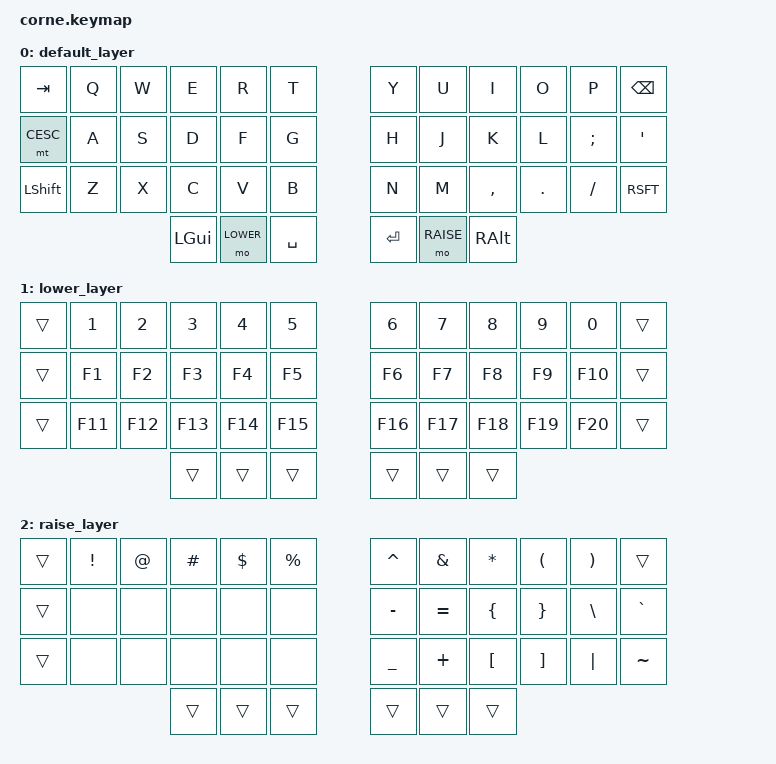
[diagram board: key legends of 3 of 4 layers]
/*
 * Copyright (c) 2020 The ZMK Contributors
 *
 * SPDX-License-Identifier: MIT
 */

#include <behaviors.dtsi>
#include <dt-bindings/zmk/keys.h>
#include <dt-bindings/zmk/bt.h>
#include <dt-bindings/zmk/outputs.h>

#define DEFAULT 0
#define LOWER   1
#define RAISE   2
#define ADJUST  3

#define CESC LCTRL ESC
#define BS(X) BT_SEL X


// Tapping term for mod-tap
&mt {
    tapping-term-ms = <150>;
};

&soft_off {
    hold-time-ms = <3000>;
};

/ {
        conditional_layers {
                compatible = "zmk,conditional-layers";
                tri_layer {
                        if-layers = <LOWER RAISE>;
                        then-layer = <ADJUST>;
                };
        };

        keymap {
                compatible = "zmk,keymap";

                default_layer {
                        bindings = <
//|--------+--------+--------+--------+--------+--------|                    |--------+--------+--------+--------+--------+--------|
    &kp TAB    &kp Q    &kp W    &kp E    &kp R    &kp T                         &kp Y    &kp U    &kp I    &kp O    &kp P &kp BSPC
//|--------+--------+--------+--------+--------+--------|                    |--------+--------+--------+--------+--------+--------|
   &mt CESC    &kp A    &kp S    &kp D    &kp F    &kp G                         &kp H    &kp J    &kp K    &kp L &kp SEMI  &kp SQT
//|--------+--------+--------+--------+--------+--------|                    |--------+--------+--------+--------+--------+--------|
   &kp LSHFT   &kp Z    &kp X    &kp C    &kp V    &kp B                         &kp N    &kp M &kp COMMA &kp DOT &kp FSLH &kp RSFT
//|--------+--------+--------+--------+--------+--------+--------|  |--------+--------+--------+--------+--------+--------+--------|
                                     &kp LGUI &mo LOWER &kp SPACE   &kp RET  &mo RAISE &kp RALT
                                  //`----------------------------'  `--------------------------'
                        >;
                };

                lower_layer {
                        bindings = <
//|--------+--------+--------+--------+--------+--------|                    |--------+--------+--------+--------+--------+--------|
     &trans   &kp N1   &kp N2   &kp N3   &kp N4   &kp N5                        &kp N6   &kp N7   &kp N8   &kp N9   &kp N0   &trans
//|--------+--------+--------+--------+--------+--------|                    |--------+--------+--------+--------+--------+--------|
     &trans   &kp F1   &kp F2   &kp F3   &kp F4   &kp F5                        &kp F6   &kp F7   &kp F8   &kp F9  &kp F10   &trans
//|--------+--------+--------+--------+--------+--------|                    |--------+--------+--------+--------+--------+--------|
     &trans  &kp F11  &kp F12  &kp F13  &kp F14  &kp F15                       &kp F16  &kp F17  &kp F18  &kp F19  &kp F20   &trans
//|--------+--------+--------+--------+--------+--------+--------|  |--------+--------+--------+--------+--------+--------+--------|
                                         &trans   &trans   &trans      &trans   &trans   &trans
                                  //`----------------------------'  `--------------------------'
                        >;
                };

                raise_layer {
                        bindings = <
//|--------+--------+--------+--------+--------+--------|                    |--------+--------+--------+--------+--------+--------|
     &trans &kp EXCL   &kp AT &kp HASH &kp DLLR &kp PRCNT                     &kp CARET &kp AMPS &kp STAR &kp LPAR &kp RPAR  &trans
//|--------+--------+--------+--------+--------+--------|                    |--------+--------+--------+--------+--------+--------|
     &trans    &none    &none    &none    &none    &none                      &kp MINUS &kp EQUAL &kp LBRC &kp RBRC &kp BSLH &kp GRAVE
//|--------+--------+--------+--------+--------+--------|                    |--------+--------+--------+--------+--------+--------|
     &trans    &none    &none    &none    &none    &none                      &kp UNDER &kp PLUS &kp LBKT &kp RBKT &kp PIPE &kp TILDE
//|--------+--------+--------+--------+--------+--------+--------|  |--------+--------+--------+--------+--------+--------+--------|
                                         &trans   &trans   &trans      &trans   &trans   &trans
                                  //`----------------------------'  `--------------------------'
                        >;
                };

                adjust_layer {
                        bindings = <
//|--------+--------+--------+--------+--------+--------|                    |--------+--------+--------+--------+--------+--------|
 &out OUT_TOG &bt BS(0) &bt BS(1) &bt BS(2) &bt BS(3) &bt BS(4)                 &kp HOME &kp PGDN &kp PGUP  &kp END    &none  &kp DEL
//|--------+--------+--------+--------+--------+--------|                    |--------+--------+--------+--------+--------+--------|
     &trans    &none    &none    &none    &none &bt BT_CLR                    &kp LEFT &kp DOWN   &kp UP &kp RIGHT   &none    &none
//|--------+--------+--------+--------+--------+--------|                    |--------+--------+--------+--------+--------+--------|
     &trans    &none    &none    &none    &none &bootloader                 &bootloader   &none    &none    &none    &none    &none
//|--------+--------+--------+--------+--------+--------+--------|  |--------+--------+--------+--------+--------+--------+--------|
                                         &trans   &trans   &trans      &trans   &trans   &trans
                                  //`----------------------------'  `--------------------------'
                        >;
                };
        };
};
